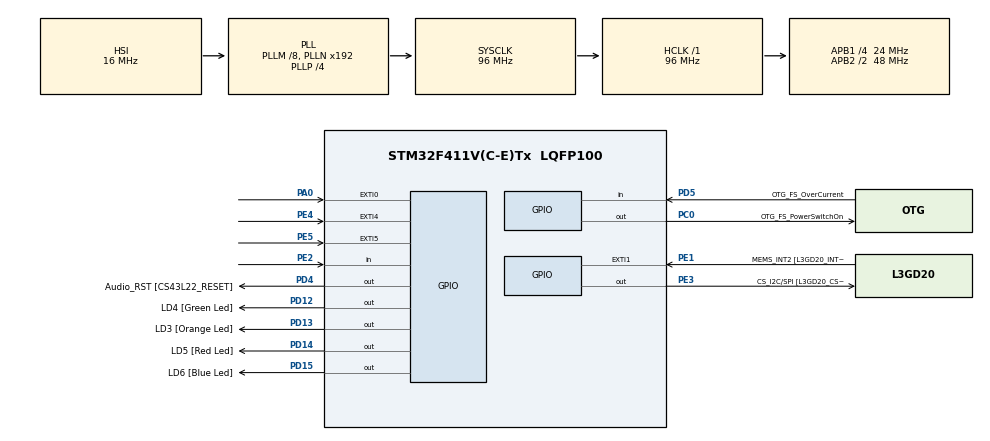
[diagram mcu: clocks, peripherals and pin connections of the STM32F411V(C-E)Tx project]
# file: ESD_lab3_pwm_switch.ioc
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Mcu.Family=STM32F4
Mcu.Name=STM32F411V(C-E)Tx
Mcu.Package=LQFP100
NVIC.PriorityGroup=NVIC_PRIORITYGROUP_0
PA0-WKUP.GPIO_ModeDefaultEXTI=GPIO_MODE_EVT_RISING
PA0-WKUP.Signal=GPXTI0
PA10.GPIO_Label=OTG_FS_ID
PA10.Signal=USB_OTG_FS_ID
PA11.GPIO_Label=OTG_FS_DM
PA11.Signal=USB_OTG_FS_DM
PA12.GPIO_Label=OTG_FS_DP
PA12.Signal=USB_OTG_FS_DP
PA13.GPIO_Label=SWDIO
PA13.Signal=SYS_JTMS-SWDIO
PA14.GPIO_Label=SWCLK
PA14.Signal=SYS_JTCK-SWCLK
PA4.GPIO_Label=I2S3_WS [CS43L22_LRCK]
PA4.GPIO_Mode=GPIO_MODE_AF_PP
PA4.GPIO_PuPd=GPIO_NOPULL
PA4.GPIO_Speed=GPIO_SPEED_FREQ_LOW
PA4.Signal=I2S3_WS
PA5.GPIO_Label=SPI1_SCK [L3GD20_SC/SPC]
PA5.Signal=SPI1_SCK
PA6.GPIO_Label=SPI1_MISO [L3GD20_AS0/SDO]
PA6.Signal=SPI1_MISO
PA7.GPIO_Label=SPI1_MOSI [L3GD20_SDA/SDI/SDO]
PA7.Signal=SPI1_MOSI
PA9.GPIO_Label=VBUS_FS
PA9.Signal=USB_OTG_FS_VBUS
PB10.GPIO_Label=CLK_IN [MP45DT02_CLK]
PB10.Signal=I2S2_CK
PB12.Signal=I2S2_WS
PB3.GPIO_Label=SWO
PB3.Signal=SYS_JTDO-SWO
PB6.GPIO_Label=Audio_SCL [CS43L22_SCL]
PB6.GPIO_Mode=GPIO_MODE_AF_OD
PB6.GPIO_PuPd=GPIO_NOPULL
PB6.GPIO_Speed=GPIO_SPEED_FREQ_LOW
PB6.Signal=I2C1_SCL
PB9.GPIO_Label=Audio_SDA [CS43L22_SDA]
PB9.GPIO_Mode=GPIO_MODE_AF_OD
PB9.GPIO_PuPd=GPIO_NOPULL
PB9.GPIO_Speed=GPIO_SPEED_FREQ_LOW
PB9.Signal=I2C1_SDA
PC0.GPIO_Label=OTG_FS_PowerSwitchOn
PC0.PinState=GPIO_PIN_SET
PC0.Signal=GPIO_Output
PC10.GPIO_Label=I2S3_SCK [CS43L22_SCLK]
PC10.GPIO_Mode=GPIO_MODE_AF_PP
PC10.GPIO_PuPd=GPIO_NOPULL
PC10.GPIO_Speed=GPIO_SPEED_FREQ_LOW
PC10.Signal=I2S3_CK
PC12.GPIO_Label=I2S3_SD [CS43L22_SDIN]
PC12.GPIO_Mode=GPIO_MODE_AF_PP
PC12.GPIO_PuPd=GPIO_NOPULL
PC12.GPIO_Speed=GPIO_SPEED_FREQ_LOW
PC12.Signal=I2S3_SD
PC14-OSC32_IN.GPIO_Label=PC14-OSC32_IN
PC14-OSC32_IN.Signal=RCC_OSC32_IN
PC15-OSC32_OUT.GPIO_Label=PC15-OSC32_OUT
PC15-OSC32_OUT.Signal=RCC_OSC32_OUT
PC3.GPIO_Label=PDM_OUT [MP45DT02_DOUT]
PC3.Signal=I2S2_SD
PC7.GPIO_Label=I2S3_MCK [CS43L22_MCLK]
PC7.GPIO_Mode=GPIO_MODE_AF_PP
PC7.GPIO_PuPd=GPIO_NOPULL
PC7.GPIO_Speed=GPIO_SPEED_FREQ_LOW
PC7.Signal=I2S3_MCK
PD12.GPIO_Label=LD4 [Green Led]
PD12.GPIO_PuPd=GPIO_NOPULL
PD12.GPIO_Speed=GPIO_SPEED_FREQ_LOW
PD12.Signal=GPIO_Output
PD13.GPIO_Label=LD3 [Orange Led]
PD13.GPIO_PuPd=GPIO_NOPULL
PD13.GPIO_Speed=GPIO_SPEED_FREQ_LOW
PD13.Signal=GPIO_Output
PD14.GPIO_Label=LD5 [Red Led]
PD14.GPIO_PuPd=GPIO_NOPULL
PD14.GPIO_Speed=GPIO_SPEED_FREQ_LOW
PD14.Signal=GPIO_Output
PD15.GPIO_Label=LD6 [Blue Led]
PD15.GPIO_PuPd=GPIO_NOPULL
PD15.GPIO_Speed=GPIO_SPEED_FREQ_LOW
PD15.Signal=GPIO_Output
PD4.GPIO_Label=Audio_RST [CS43L22_RESET]
PD4.Signal=GPIO_Output
PD5.GPIO_Label=OTG_FS_OverCurrent
PD5.Signal=GPIO_Input
PE1.GPIO_Label=MEMS_INT2 [L3GD20_INT2]
PE1.GPIO_ModeDefaultEXTI=GPIO_MODE_EVT_RISING
PE1.Signal=GPXTI1
PE2.Signal=GPIO_Input
PE3.GPIO_Label=CS_I2C/SPI [L3GD20_CS_I2C/SPI]
PE3.Signal=GPIO_Output
PE4.GPIO_ModeDefaultEXTI=GPIO_MODE_EVT_RISING
PE4.Signal=GPXTI4
PE5.GPIO_ModeDefaultEXTI=GPIO_MODE_EVT_RISING
PE5.Signal=GPXTI5
PH0\ -\ OSC_IN.GPIO_Label=PH0-OSC_IN
PH0\ -\ OSC_IN.Signal=RCC_OSC_IN
PH1\ -\ OSC_OUT.GPIO_Label=PH1-OSC_OUT
PH1\ -\ OSC_OUT.Signal=RCC_OSC_OUT
ProjectManager.HeapSize=0x200
ProjectManager.StackSize=0x400
ProjectManager.TargetToolchain=STM32CubeIDE
RCC.48MHZClocksFreq_Value=48000000
RCC.AHBFreq_Value=96000000
RCC.APB1CLKDivider=RCC_HCLK_DIV4
RCC.APB1Freq_Value=24000000
RCC.APB1TimFreq_Value=48000000
RCC.APB2CLKDivider=RCC_HCLK_DIV2
RCC.APB2Freq_Value=48000000
RCC.APB2TimFreq_Value=96000000
RCC.CortexFreq_Value=96000000
RCC.HCLKFreq_Value=96000000
RCC.HSE_VALUE=8000000
RCC.HSI_VALUE=16000000
RCC.LSE_VALUE=32768
RCC.PLLI2SM=5
RCC.PLLI2SN=200
RCC.PLLM=8
RCC.PLLP=RCC_PLLP_DIV4
RCC.PLLQ=8
RCC.SYSCLKFreq_VALUE=96000000
RCC.SYSCLKSource=RCC_SYSCLKSOURCE_PLLCLK
RCC.VCOOutputFreq_Value=384000000
board=STM32F411E-DISCO

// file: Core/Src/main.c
/* USER CODE BEGIN Header */
/**
  ******************************************************************************
  * @file           : main.c
  * @brief          : Main program body
  ******************************************************************************
  * @attention
  *
  * Copyright (c) 2023 STMicroelectronics.
  * All rights reserved.
  *
  * This software is licensed under terms that can be found in the LICENSE file
  * in the root directory of this software component.
  * If no LICENSE file comes with this software, it is provided AS-IS.
  *
  ******************************************************************************
  */
/* USER CODE END Header */
#include "main.h"
#include <stdio.h>
/* USER CODE BEGIN Includes */
#define RCC_GPIOD_ENR (0b01 << 3)	// Enable GPIOD clock
// Defines for EXTI (External Interrupt) configuration
#define EXTI_RTSR_PORTA0 (0b01)         // Rising edge trigger for EXTI line 0 (PortA Pin 0)
#define EXTI_IMR_PORTA0 (0b01)          // Enable interrupt for EXTI line 0 (PortA Pin 0)
#define EXTI_PR1_PR0 (0b01)             // Clear pending bit for EXTI line 0 (PortA Pin 0)
#define DUTYCYCLE_5 50
#define DUTYCYCLE_10 100
#define DUTYCYCLE_95 950
#define DUTYCYCLE_100 1000
#define RCC_TIM2_ENR (0b01)
#define TIM2_DIER_UIE (0b01)
#define TIM2_DIER_TIE (0b01 << 6)
volatile int up_down;
volatile uint8_t buttonPressed = 0;

/* USER CODE END Includes */

void SystemClock_Config(void);
void USART2_Config(void);
void PWM_Config(void);
void TIM2_IRQHandler(void);
void UART2_TxChar(char ch);
char UART2_RxChar();
static void TIM2_Init(void);

int main(void)
{

	// Initialize system, configure UART, and set up PWM.

      USART2_Config();

      PWM_Config();
      TIM2_Init();
      char rxData;
   //   Initializing the GPIO with a duty cycle of 60%
      TIM4->CCR1=600;
      up_down=1;
      while (1) {
    	  rxData = UART2_RxChar();
    	  printf("\n\r");
    	  UART2_TxChar(rxData);
    	  	  if(rxData=='A'){

              // Adjust the duty cycle (CCR1) for the PWM
    	  		  if(TIM4->CCR1>=1000 ){
              TIM4->CCR1 =TIM4->CCR1; // Modify this value as needed

    	  		  }else
    	  		  {
    	  			TIM4->CCR1 =TIM4->CCR1 + DUTYCYCLE_5;

    	  		  }

    	  	  }
    	  	  else if(rxData=='B'){

    	  		 if(TIM4->CCR1==0 ){
    	  		        TIM4->CCR1 =TIM4->CCR1; // Modify this value as needed

    	  		 }else
    	  		  {
    	  			 TIM4->CCR1 =TIM4->CCR1 - DUTYCYCLE_5;

    	  		   }

    	  	  }
              else if(rxData=='P'){
            	  printf("\n\r duty cycle is %lu\n\r",(TIM4->CCR1)/10);

              }
    	  	   printf("\n\r duty cycle is %lu\n\r",(TIM4->CCR1)/10);
          }

          return 0;
  /* USER CODE END 3 */
}

void SystemClock_Config(void)
{
  RCC_OscInitTypeDef RCC_OscInitStruct = {0};
  RCC_ClkInitTypeDef RCC_ClkInitStruct = {0};

  /** Configure the main internal regulator output voltage
  */
  __HAL_RCC_PWR_CLK_ENABLE();
  __HAL_PWR_VOLTAGESCALING_CONFIG(PWR_REGULATOR_VOLTAGE_SCALE1);

  /** Initializes the RCC Oscillators according to the specified parameters
  * in the RCC_OscInitTypeDef structure.
  */
  RCC_OscInitStruct.OscillatorType = RCC_OSCILLATORTYPE_HSI;
  RCC_OscInitStruct.HSIState = RCC_HSI_ON;
  RCC_OscInitStruct.HSICalibrationValue = RCC_HSICALIBRATION_DEFAULT;
  RCC_OscInitStruct.PLL.PLLState = RCC_PLL_ON;
  RCC_OscInitStruct.PLL.PLLSource = RCC_PLLSOURCE_HSI;
  RCC_OscInitStruct.PLL.PLLM = 8;
  RCC_OscInitStruct.PLL.PLLN = 192;
  RCC_OscInitStruct.PLL.PLLP = RCC_PLLP_DIV4;
  RCC_OscInitStruct.PLL.PLLQ = 8;
  if (HAL_RCC_OscConfig(&RCC_OscInitStruct) != HAL_OK)
  {
    Error_Handler();
  }

  /** Initializes the CPU, AHB and APB buses clocks
  */
  RCC_ClkInitStruct.ClockType = RCC_CLOCKTYPE_HCLK|RCC_CLOCKTYPE_SYSCLK
                              |RCC_CLOCKTYPE_PCLK1|RCC_CLOCKTYPE_PCLK2;
  RCC_ClkInitStruct.SYSCLKSource = RCC_SYSCLKSOURCE_PLLCLK;
  RCC_ClkInitStruct.AHBCLKDivider = RCC_SYSCLK_DIV1;
  RCC_ClkInitStruct.APB1CLKDivider = RCC_HCLK_DIV4;
  RCC_ClkInitStruct.APB2CLKDivider = RCC_HCLK_DIV2;

  if (HAL_RCC_ClockConfig(&RCC_ClkInitStruct, FLASH_LATENCY_3) != HAL_OK)
  {
    Error_Handler();
  }
}

/**
 *
  * @brief Configure USART2 for UART communication
  * @param None
  * @retval None
  */
void USART2_Config(void) {
    // Enable USART2 and GPIOA clocks
    RCC->AHB1ENR |= RCC_AHB1ENR_GPIOAEN;
    RCC->APB1ENR |= RCC_APB1ENR_USART2EN;

    // Configure GPIO pins for USART2 (PA2 = Tx, PA3 = Rx)
    GPIOA->AFR[0] = (7 << (4 * 2)) | (7 << (4 * 3));
    GPIOA->MODER = (GPIOA->MODER & ~(3 << (2 * 2))) | (2 << (2 * 2)) | (2 << (2 * 3));

    // Configure USART2
    USART2->BRR = 0x683; // 9600 baud rate @ 16MHz
    USART2->CR1 = USART_CR1_TE | USART_CR1_RE  | USART_CR1_UE; // Enable transmitter and USART

}

/**
  * @brief Transmit a character via UART2
  * @param ch: Character to be transmitted
  */
void UART2_TxChar(char ch) {
    while (!(USART2->SR & USART_SR_TXE))
    	{
    	;
    	}

    USART2->DR = ch;
}

/**
  * @brief Receive a character via UART2
  * @return Received character
  */
char UART2_RxChar() {
    while (!(USART2->SR & USART_SR_RXNE));
    return USART2->DR;
}
/**
  * @brief Configure PWM for controlling a device or component
  */
// Function to configure PWM for the green LED (PD12)
void PWM_Config(void) {

    // Enable TIM4 clock
    RCC->APB1ENR |= RCC_APB1ENR_TIM4EN;
    RCC->AHB1ENR |=  RCC_GPIOD_ENR;
    // Configure TIM4 for PWM generation
    TIM4->PSC = 0;  // Prescaler
    TIM4->ARR = 999; // Auto-reload register
    TIM4->CCMR1 = TIM_CCMR1_OC1M_1 | TIM_CCMR1_OC1M_2; // PWM mode 1 (for Channel 1)
    TIM4->CCER = TIM_CCER_CC1E; // Enable capture/compare channel 1
    TIM4->CR1 = TIM_CR1_CEN; // Enable timer

    // Configure GPIO pin for the green LED (PD12)
    GPIOD->MODER |= GPIO_MODER_MODER12_1; // Alternate function mode
    GPIOD->AFR[1] |= (2 << (4 * 4)); // AF2 (TIM4_CH1) for PD12

    // Configure EXTI for PortA Pin 0 (external interrupt)
      EXTI->IMR |= EXTI_IMR_PORTA0;
      EXTI->RTSR |= EXTI_RTSR_PORTA0;

      // Enable EXTI0_IRQn (External Interrupt 0) in NVIC
      NVIC_EnableIRQ(EXTI0_IRQn);
}

int _write(int file, char *ptr, int len) {
    int i;
    for (i = 0; i < len; i++) {
        while (!(USART2->SR & USART_SR_TXE));  // Wait until TX buffer is empty
        USART2->DR = (ptr[i] & 0xFF);  // Send a character
    }
    return len;
}

// Function to initialize TIM2 (Timer 2)
static void TIM2_Init(void)
{
	// Enable clock for TIM2
	RCC->APB1ENR |= RCC_TIM2_ENR;

	// Configure TIM2 settings (interrupts, prescaler, and auto-reload value)
	TIM2->DIER |= TIM2_DIER_UIE ;
	TIM2->DIER |= TIM2_DIER_TIE ;
	TIM2->PSC=0xFF;			 // Prescaler value
	TIM2->ARR=50625;		 // Auto-reload value for a 270ms delay

	 // Enable TIM2_IRQn (TIM2 global interrupt) in NVIC
	 NVIC_EnableIRQ(TIM2_IRQn);

}

// TIM2 interrupt handler
void TIM2_IRQHandler(void) {
	if (TIM2->SR & TIM_SR_UIF) {
	        TIM2->SR &= ~TIM_SR_UIF; // Clear the update interrupt flag

	        if (buttonPressed) {
	        	if(TIM4->CCR1<=DUTYCYCLE_5)
	        			 {
	        			//Increasing the duty cycle by 10%
	        				 TIM4->CCR1=TIM4->CCR1+DUTYCYCLE_10;
	        				 up_down=1;
	        			 }
	        		else if((TIM4->CCR1>=DUTYCYCLE_95) || (up_down==0)){
	        			//Decreasing duty cycle by 10%
	        			 TIM4->CCR1=TIM4->CCR1-DUTYCYCLE_10;
	        			 up_down=0;

	        		 }else if(up_down==1)
	        		 {
	        			 //Increasing the duty cycle by 10%
	        			 TIM4->CCR1=TIM4->CCR1+DUTYCYCLE_10;
	        		 }
	            	            printf("\n\rButton debounced and processed.\n\r");
	            buttonPressed = 0; // Reset button press state
	        }
	    }
}
/**
  * @brief Handle the EXTI0 (External Interrupt 0) interrupt
  * @note This function is an interrupt handler.
  */
void EXTI0_IRQHandler(void) {
    if (EXTI->PR & EXTI_PR1_PR0) {
        EXTI->PR |= EXTI_PR1_PR0; // Clear pending bit for EXTI line 0 (PortA Pin 0)

        if (!buttonPressed) {
            TIM2->CR1 |= TIM_CR1_CEN; // Start Timer 2 for debouncing
            buttonPressed = 1; // Set button press state
        }
    }
}

void Error_Handler(void)
{
  __disable_irq();
  while (1)
  {
  }
}
